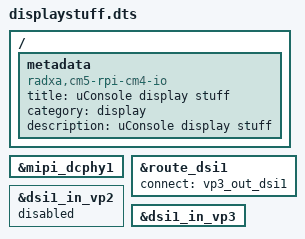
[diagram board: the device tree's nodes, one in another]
/dts-v1/;
/plugin/;

#include <dt-bindings/interrupt-controller/irq.h>
#include <dt-bindings/gpio/gpio.h>
#include <dt-bindings/pinctrl/rockchip.h>

/ {
	metadata {
		title = "uConsole display stuff";
		compatible = "radxa,cm5-rpi-cm4-io";
		category = "display";
		description = "uConsole display stuff";
	};
};

&mipi_dcphy1 {
	status = "okay";
};

&route_dsi1 {
	status = "okay";
	connect = <&vp3_out_dsi1>;
};

&dsi1_in_vp2 {
	status = "disabled";
};

&dsi1_in_vp3 {
	status = "okay";
};
